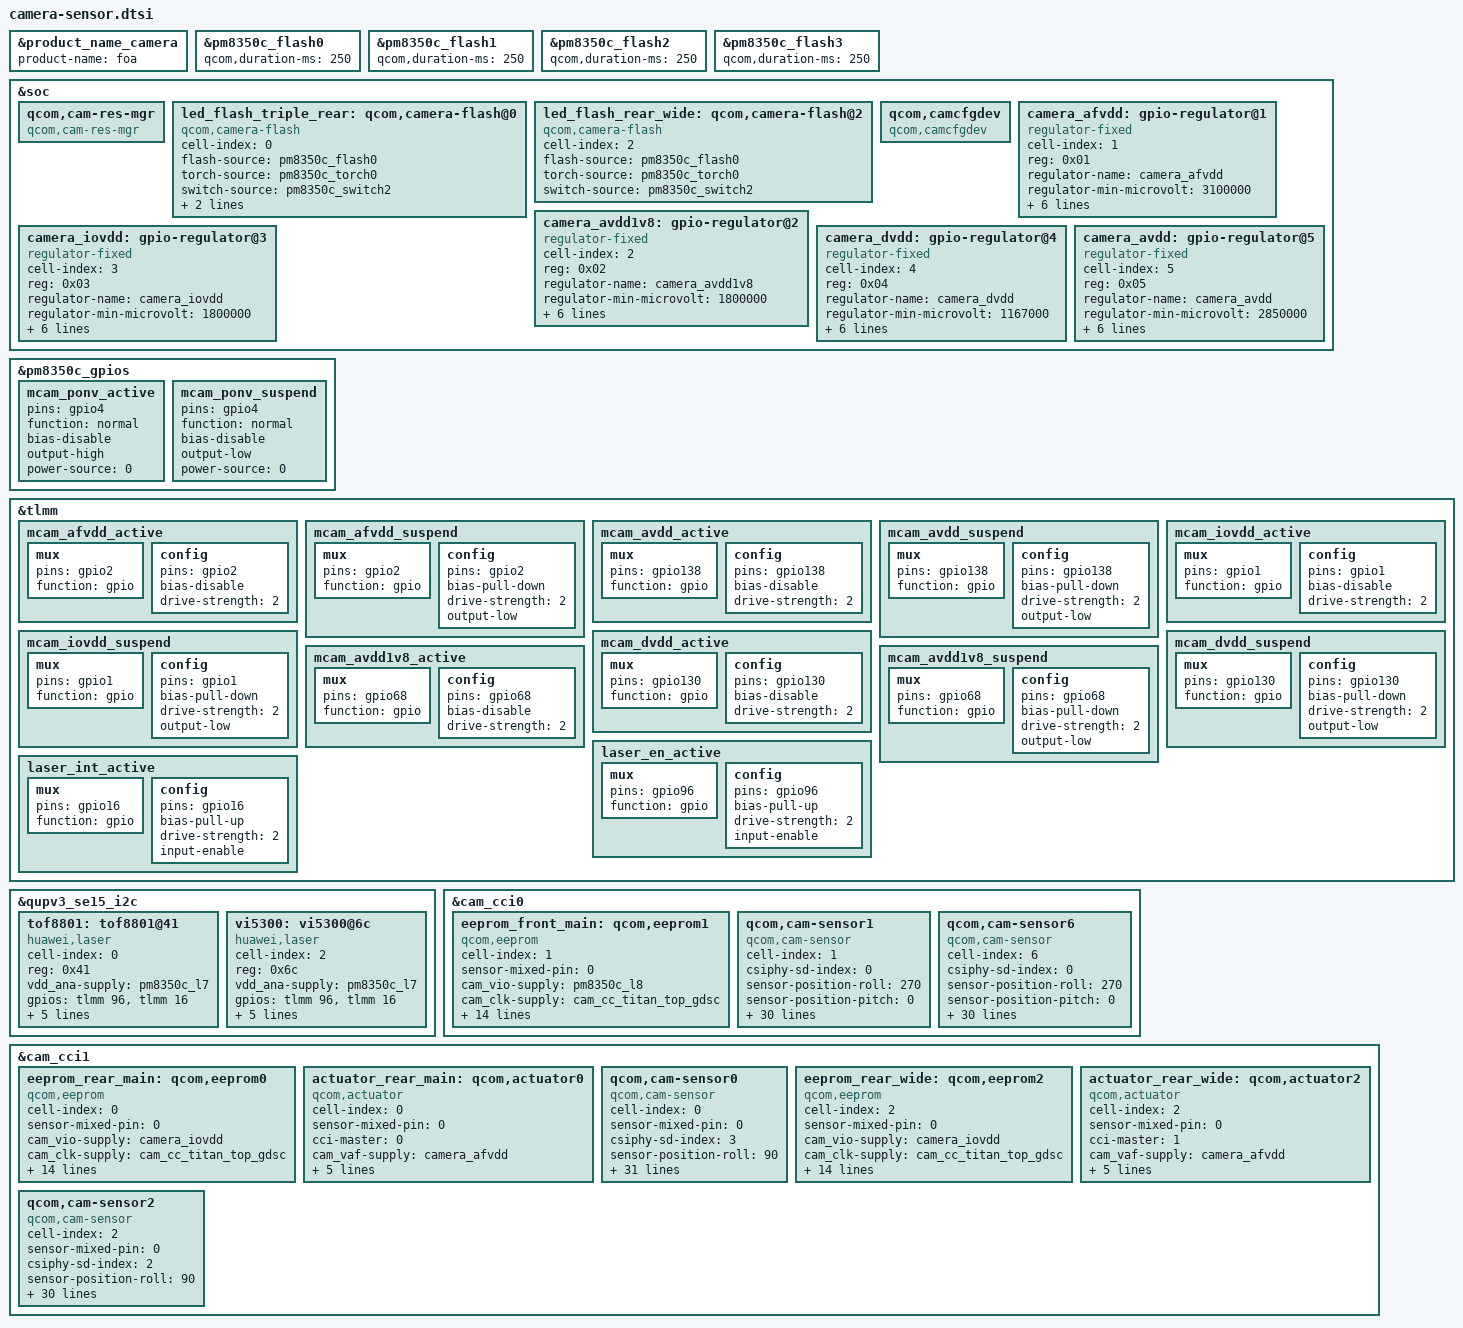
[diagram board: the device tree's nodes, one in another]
#include <dt-bindings/clock/qcom,camcc-yupik.h>

&product_name_camera {
	product-name = "foa";
};

&pm8350c_flash0 {
	qcom,duration-ms = <250>;
};

&pm8350c_flash1 {
	qcom,duration-ms = <250>;
};

&pm8350c_flash2 {
	qcom,duration-ms = <250>;
};

&pm8350c_flash3 {
	qcom,duration-ms = <250>;
};

&soc {
	qcom,cam-res-mgr {
		compatible = "qcom,cam-res-mgr";
		status = "ok";
	};

	led_flash_triple_rear: qcom,camera-flash@0 {
		cell-index = <0>;
		compatible = "qcom,camera-flash";
		flash-source = <&pm8350c_flash0>;
		torch-source = <&pm8350c_torch0>;
		switch-source = <&pm8350c_switch2>;
		torch-light-num = <0>;
		torch-light-name = "torch-light0";
		status = "ok";
	};

	led_flash_rear_wide: qcom,camera-flash@2 {
		cell-index = <2>;
		compatible = "qcom,camera-flash";
		flash-source = <&pm8350c_flash0>;
		torch-source = <&pm8350c_torch0>;
		switch-source = <&pm8350c_switch2>;
		status = "ok";
	};

	qcom,camcfgdev {
		compatible = "qcom,camcfgdev";
		status = "ok";
	};

	camera_afvdd: gpio-regulator@1 {
		cell-index = <1>;
		compatible = "regulator-fixed";
		reg = <0x01>;
		regulator-name = "camera_afvdd";
		regulator-min-microvolt = <3100000>;
		regulator-max-microvolt = <3100000>;
		gpio = <&tlmm 2 0>;
		pinctrl-names = "cam_default", "cam_suspend";
		pinctrl-0 = <&mcam_afvdd_active>;
		pinctrl-1 = <&mcam_afvdd_suspend>;
		startup-delay-us = <1000>;
		enable-active-high;
	};

	camera_avdd1v8: gpio-regulator@2 {
		cell-index = <2>;
		compatible = "regulator-fixed";
		reg = <0x02>;
		regulator-name = "camera_avdd1v8";
		regulator-min-microvolt = <1800000>;
		regulator-max-microvolt = <1800000>;
		gpio = <&tlmm 68 0>;
		pinctrl-names = "cam_default", "cam_suspend";
		pinctrl-0 = <&mcam_avdd1v8_active>;
		pinctrl-1 = <&mcam_avdd1v8_suspend>;
		startup-delay-us = <1000>;
		enable-active-high;
	};

	camera_iovdd: gpio-regulator@3 {
		cell-index = <3>;
		compatible = "regulator-fixed";
		reg = <0x03>;
		regulator-name = "camera_iovdd";
		regulator-min-microvolt = <1800000>;
		regulator-max-microvolt = <1800000>;
		gpio = <&tlmm 1 0>;
		pinctrl-names = "cam_default", "cam_suspend";
		pinctrl-0 = <&mcam_iovdd_active>;
		pinctrl-1 = <&mcam_iovdd_suspend>;
		startup-delay-us = <1000>;
		enable-active-high;
	};

	camera_dvdd: gpio-regulator@4 {
		cell-index = <4>;
		compatible = "regulator-fixed";
		reg = <0x04>;
		regulator-name = "camera_dvdd";
		regulator-min-microvolt = <1167000>;
		regulator-max-microvolt = <1167000>;
		gpio = <&tlmm 130 0>;
		pinctrl-names = "cam_default", "cam_suspend";
		pinctrl-0 = <&mcam_dvdd_active>;
		pinctrl-1 = <&mcam_dvdd_suspend>;
		startup-delay-us = <1000>;
		enable-active-high;
	};

	camera_avdd: gpio-regulator@5 {
		cell-index = <5>;
		compatible = "regulator-fixed";
		reg = <0x05>;
		regulator-name = "camera_avdd";
		regulator-min-microvolt = <2850000>;
		regulator-max-microvolt = <2850000>;
		gpio = <&tlmm 138 0>;
		pinctrl-names = "cam_default", "cam_suspend";
		pinctrl-0 = <&mcam_avdd_active>;
		pinctrl-1 = <&mcam_avdd_suspend>;
		startup-delay-us = <1000>;
		enable-active-high;
	};
};

&pm8350c_gpios {
	mcam_ponv_active: mcam_ponv_active {
		pins = "gpio4";
		function = "normal";
		bias-disable;
		output-high;
		power-source = <0>;
	};
	mcam_ponv_suspend: mcam_ponv_suspend {
		pins = "gpio4";
		function = "normal";
		bias-disable;
		output-low;
		power-source = <0>;
	};
};

&tlmm {
	mcam_afvdd_active: mcam_afvdd_active {
		/* mcam_afvdd for REAR MAIN, REAR WIDE*/
		mux {
			pins = "gpio2";
			function = "gpio";
		};

		config {
			pins = "gpio2";
			bias-disable; /* No PULL */
			drive-strength = <2>; /* 2 MA */
		};
	};

	mcam_afvdd_suspend: mcam_afvdd_suspend {
		/* mcam_avdd */
		mux {
			pins = "gpio2";
			function = "gpio";
		};

		config {
			pins = "gpio2";
			bias-pull-down; /* PULL DOWN */
			drive-strength = <2>; /* 2 MA */
			output-low;
		};
	};

	mcam_avdd_active: mcam_avdd_active {
		/* mcam_avdd */
		mux {
			pins = "gpio138";
			function = "gpio";
		};

		config {
			pins = "gpio138";
			bias-disable; /* No PULL */
			drive-strength = <2>; /* 2 MA */
		};
	};

	mcam_avdd_suspend: mcam_avdd_suspend {
		/* mcam_avdd */
		mux {
			pins = "gpio138";
			function = "gpio";
		};

		config {
			pins = "gpio138";
			bias-pull-down; /* PULL DOWN */
			drive-strength = <2>; /* 2 MA */
			output-low;
		};
	};

	mcam_iovdd_active: mcam_iovdd_active {
		/* mcam_iovdd for REAR MAIN, REAR WIDE */
		mux {
			pins = "gpio1";
			function = "gpio";
		};

		config {
			pins = "gpio1";
			bias-disable; /* No PULL */
			drive-strength = <2>; /* 2 MA */
		};
	};

	mcam_iovdd_suspend: mcam_iovdd_suspend {
		/* mcam_iovdd for REAR MAIN, REAR WIDE */
		mux {
			pins = "gpio1";
			function = "gpio";
		};

		config {
			pins = "gpio1";
			bias-pull-down; /* PULL DOWN */
			drive-strength = <2>; /* 2 MA */
			output-low;
		};
	};

	mcam_dvdd_active: mcam_dvdd_active {
		/* mcam_dvdd */
		mux {
			pins = "gpio130";
			function = "gpio";
		};

		config {
			pins = "gpio130";
			bias-disable; /* No PULL */
			drive-strength = <2>; /* 2 MA */
		};
	};

	mcam_dvdd_suspend: mcam_dvdd_suspend {
		/* mcam_dvdd */
		mux {
			pins = "gpio130";
			function = "gpio";
		};

		config {
			pins = "gpio130";
			bias-pull-down; /* PULL DOWN */
			drive-strength = <2>; /* 2 MA */
			output-low;
		};
	};

	mcam_avdd1v8_active: mcam_avdd1v8_active {
		/* mcam_avdd */
		mux {
			pins = "gpio68";
			function = "gpio";
		};

		config {
			pins = "gpio68";
			bias-disable; /* No PULL */
			drive-strength = <2>; /* 2 MA */
		};
	};

	mcam_avdd1v8_suspend: mcam_avdd1v8_suspend {
		/* mcam_avdd */
		mux {
			pins = "gpio68";
			function = "gpio";
		};

		config {
			pins = "gpio68";
			bias-pull-down; /* PULL DOWN */
			drive-strength = <2>; /* 2 MA */
			output-low;
		};
	};

	laser_en_active: laser_en_active {
		/* laser en pin */
		mux {
			pins = "gpio96";
			function = "gpio";
		};

		config {
			pins = "gpio96";
			bias-pull-up; /* PULL UP */
			drive-strength = <2>; /* 2 MA */
			input-enable;
		};
	};

	laser_int_active: laser_int_active {
		/* laser int pin */
		mux {
			pins = "gpio16";
			function = "gpio";
		};

		config {
			pins = "gpio16";
			bias-pull-up; /* PULL UP */
			drive-strength = <2>; /* 2 MA */
			input-enable;
		};
	};
};

/* laser */
&qupv3_se15_i2c {
	status = "ok";

	tof8801: tof8801@41 {
		cell-index = <0>;
		compatible = "huawei,laser";
		reg = <0x41>;
		vdd_ana-supply = <&pm8350c_l7>;
		gpios = <&tlmm 96 0>,
			<&tlmm 16 0>;
		pinctrl-names = "laser_int_active", "laser_en_active";
		pinctrl-0 = <&laser_int_active>;
		pinctrl-1 = <&laser_en_active>;
		gpio-req-tbl-num = <0>;
		gpio-req-tbl-flags = <0>;
		gpio-req-tbl-label = "CAM_VAF0";
		status = "ok";
	};

	vi5300: vi5300@6c {
		cell-index = <2>;
		compatible = "huawei,laser";
		reg = <0x6c>;
		vdd_ana-supply = <&pm8350c_l7>;
		gpios = <&tlmm 96 0>,
			<&tlmm 16 0>;
		pinctrl-names = "laser_int_active", "laser_en_active";
		pinctrl-0 = <&laser_int_active>;
		pinctrl-1 = <&laser_en_active>;
		gpio-req-tbl-num = <0>;
		gpio-req-tbl-flags = <0>;
		gpio-req-tbl-label = "CAM_VAF0";
		status = "ok";
	};
};

/* cci0: i2c0 i2c1 */
&cam_cci0 {
	/* front main eeprom */
	eeprom_front_main: qcom,eeprom1 {
		cell-index = <1>; /* slotId 1 */
		compatible = "qcom,eeprom";
		sensor-mixed-pin = <0>;
		cam_vio-supply = <&pm8350c_l8>; /* iovdd pm8350c l8 1.8v */
		cam_clk-supply = <&cam_cc_titan_top_gdsc>;
		regulator-names = "cam_vio", "cam_clk";
		rgltr-cntrl-support;
		rgltr-min-voltage = <1800000 0>;
		rgltr-max-voltage = <1850000 0>;
		rgltr-load-current = <40000 0>;
		gpio-no-mux = <0>;
		gpios = <&tlmm 64 0>; /* mclk0 gpio 64 */
		gpio-req-tbl-num = <0>;
		gpio-req-tbl-flags = <1>;
		gpio-req-tbl-label = "CAMIF_MCLK0";
		cci-master = <0>;
		status = "ok";
		clocks = <&camcc CAM_CC_MCLK0_CLK>;
		clock-names = "cam_clk";
		clock-cntl-level = "nominal";
		clock-rates = <19200000>;
	};

	/* front main senosr */
	qcom,cam-sensor1 {
		cell-index = <1>; /* slotId 1 */
		compatible = "qcom,cam-sensor";
		csiphy-sd-index = <0>; /* phy0 */
		sensor-position-roll = <270>;
		sensor-position-pitch = <0>;
		sensor-position-yaw = <0>;
		eeprom-src = <&eeprom_front_main>;
		sensor-mixed-pin = <0>;
		cam_vana-supply = <&camera_avdd>; /* mcam avdd 2.85v */
		cam_vaf-supply = <&camera_afvdd>; /* mcam afvdd 3.1v */
		cam_vio-supply = <&pm8350c_l8>; /* iovdd pm8350c l8 1.8v */
		cam_vdig-supply = <&camera_dvdd>; /* mcan dvdd 1.167v */
		cam_clk-supply = <&cam_cc_titan_top_gdsc>;
		regulator-names = "cam_vana", "cam_vaf", "cam_vio", "cam_vdig", "cam_clk";
		rgltr-cntrl-support;
		rgltr-min-voltage = <2850000 3100000 1800000 1167000 0>;
		rgltr-max-voltage = <2850000 3100000 1850000 1167000 0>;
		rgltr-load-current = <0 0 40000 0 0>;
		gpio-no-mux = <0>;
		pinctrl-names = "cam_default", "cam_suspend";
		pinctrl-0 = <&cam_sensor_mclk0_active>;
		pinctrl-1 = <&cam_sensor_mclk0_suspend>;
		gpios = <&tlmm 64 0>, /* mclk0 gpio 64 */
			<&tlmm 20 0>, /* reset0 gpio 20 */
			<&pm8350c_gpios 4 0>; /* ponv pm8350c_gpios 4 */
		gpio-reset = <1>;
		gpio-mixed1 = <2>;
		gpio-req-tbl-num = <0 1 2>;
		gpio-req-tbl-flags = <1 0 0>;
		gpio-req-tbl-label =  "CAMIF_MCLK0", "CAM_RESET0", "CAM_MIXED1";
		cci-master = <0>; /* i2c0 */
		status = "ok";
		clocks = <&camcc CAM_CC_MCLK0_CLK>;
		clock-names = "cam_clk";
		clock-cntl-level = "nominal";
		clock-rates = <19200000>;
	};

	/* front swing senosr */
	qcom,cam-sensor6 {
		cell-index = <6>; /* slotId 6 */
		compatible = "qcom,cam-sensor";
		csiphy-sd-index = <0>; /* phy0 */
		sensor-position-roll = <270>;
		sensor-position-pitch = <0>;
		sensor-position-yaw = <0>;
		sensor-mixed-pin = <0>;
		cam_vana-supply = <&camera_avdd>; /* mcam avdd 2.85v */
		cam_vaf-supply = <&camera_afvdd>; /* mcam afvdd 3.1v */
		cam_vio-supply = <&pm8350c_l8>;  /* iovdd pm8350c l8 1.8v */
		cam_vdig-supply = <&camera_dvdd>; /* mcan dvdd 1.167v */
		cam_clk-supply = <&cam_cc_titan_top_gdsc>;
		regulator-names = "cam_vana", "cam_vaf", "cam_vio", "cam_vdig", "cam_clk";
		rgltr-cntrl-support;
		rgltr-min-voltage = <2850000 3100000 1800000 1167000 0>;
		rgltr-max-voltage = <2850000 3100000 1850000 1167000 0>;
		rgltr-load-current = <0 0 40000 0 0>; /* value? */
		gpio-no-mux = <0>;
		pinctrl-names = "cam_default", "cam_suspend";
		pinctrl-0 = <&cam_sensor_mclk0_active>;
		pinctrl-1 = <&cam_sensor_mclk0_suspend>;
		gpios = <&tlmm 64 0>, /* mclk0 gpio 64 */
			<&tlmm 20 0>, /* reset0 gpio 20 */
			<&pm8350c_gpios 4 0>; /* ponv pm8350c_gpios 4 */
		gpio-reset = <1>;
		gpio-mixed1 = <2>;
		gpio-req-tbl-num = <0 1 2>;
		gpio-req-tbl-flags = <1 0 0>;
		gpio-req-tbl-label = "CAMIF_MCLK0", "CAM_RESET0", "CAM_MIXED1";
		cci-master = <0>; /* i2c0 */
		status = "ok";
		clocks = <&camcc CAM_CC_MCLK0_CLK>;
		clock-names = "cam_clk";
		clock-cntl-level = "nominal";
		clock-rates = <19200000>;
		ic_position = <1>; /* CAMERA_POSITION_FORE */
	};

};

/* cci1: i2c2、i2c3 */
&cam_cci1 {
	/* rear main eeprrom */
	eeprom_rear_main: qcom,eeprom0 {
		cell-index = <0>; /* slotId 0 eeprom */
		compatible = "qcom,eeprom";
		sensor-mixed-pin = <0>;
		cam_vio-supply = <&camera_iovdd>; /* iovdd 1.8v */
		cam_clk-supply = <&cam_cc_titan_top_gdsc>;
		regulator-names = "cam_vio", "cam_clk";
		rgltr-cntrl-support;
		rgltr-min-voltage = <1800000 0>;
		rgltr-max-voltage = <1800000 0>;
		rgltr-load-current = <0 0>;
		gpio-no-mux = <0>;
		gpios = <&tlmm 66 0>; /* mclk2 gpio 66 */
		gpio-req-tbl-num = <0>;
		gpio-req-tbl-flags = <1>;
		gpio-req-tbl-label = "CAMIF_MCLK2";
		cci-master = <0>;
		status = "ok";
		clocks = <&camcc CAM_CC_MCLK2_CLK>;
		clock-names = "cam_clk";
		clock-cntl-level = "nominal";
		clock-rates = <19200000>;
	};

	/* rear main actuator */
	actuator_rear_main: qcom,actuator0 {
		cell-index = <0>;
		compatible = "qcom,actuator";
		status = "ok";
		sensor-mixed-pin = <0>;
		cci-master = <0>;
		cam_vaf-supply = <&camera_afvdd>; /* afvdd gpio2 3.1v */
		regulator-names = "cam_vaf";
		rgltr-cntrl-support;
		rgltr-min-voltage = <3100000>;
		rgltr-max-voltage = <3100000>;
		rgltr-load-current = <0>;
	};

	/* rear main senosr */
	qcom,cam-sensor0 {
		cell-index = <0>; /* slotId 0 */
		compatible = "qcom,cam-sensor";
		sensor-mixed-pin = <0>;
		csiphy-sd-index = <3>; /* phy3 */
		sensor-position-roll = <90>;
		sensor-position-pitch = <0>;
		sensor-position-yaw = <180>;
		eeprom-src = <&eeprom_rear_main>;
		actuator-src = <&actuator_rear_main>;
		led-flash-src = <&led_flash_triple_rear>;
		cam_vana-supply = <&camera_avdd>; /* mcam avdd 2.85v */
		cam_vana1-supply = <&camera_avdd1v8>;
		cam_vaf-supply = <&camera_afvdd>; /* mcam afvdd 3.1v */
		cam_vio-supply = <&camera_iovdd>; /* mcam iovdd 1.8v */
		cam_vdig-supply = <&camera_dvdd>; /* mcan dvdd 1.167v */
		cam_clk-supply = <&cam_cc_titan_top_gdsc>;
		regulator-names = "cam_vana", "cam_vana1", "cam_vaf", "cam_vio", "cam_vdig", "cam_clk";
		rgltr-cntrl-support;
		rgltr-min-voltage = <2850000 1800000 3100000 1800000 1167000 0>;
		rgltr-max-voltage = <2850000 1800000 3100000 1800000 1167000 0>;
		rgltr-load-current = <0 0 0 0 0 0>; /* value? */
		gpio-no-mux = <0>;
		pinctrl-names = "cam_default", "cam_suspend";
		pinctrl-0 = <&cam_sensor_mclk2_active>;
		pinctrl-1 = <&cam_sensor_mclk2_suspend>;
		gpios = <&tlmm 66 0>, /* mclk2 gpio 66 */
			<&tlmm 77 0>; /* reset2 gpio 77 */
		gpio-reset = <1>;
		gpio-req-tbl-num = <0 1>;
		gpio-req-tbl-flags = <1 0>;
		gpio-req-tbl-label = "CAMIF_MCLK2", "CAM_RESET2";
		cci-master = <0>; /* i2c2 */
		status = "ok";
		clocks = <&camcc CAM_CC_MCLK2_CLK>;
		clock-names = "cam_clk";
		clock-cntl-level = "nominal";
		clock-rates = <19200000>;
	};

	/* rear wide eeprom */
	eeprom_rear_wide: qcom,eeprom2 {
		cell-index = <2>; /* slotId 2 */
		compatible = "qcom,eeprom";
		sensor-mixed-pin = <0>;
		cam_vio-supply = <&camera_iovdd>; /* iovdd 1.8v */
		cam_clk-supply = <&cam_cc_titan_top_gdsc>;
		regulator-names = "cam_vio", "cam_clk";
		rgltr-cntrl-support;
		rgltr-min-voltage = <1800000 0>;
		rgltr-max-voltage = <1800000 0>;
		rgltr-load-current = <0 0>;
		gpio-no-mux = <0>;
		gpios = <&tlmm 67 0>; /* mclk3 gpio 67 */
		gpio-req-tbl-num = <0>;
		gpio-req-tbl-flags = <1>;
		gpio-req-tbl-label = "CAMIF_MCLK3";
		cci-master = <1>;
		status = "ok";
		clocks = <&camcc CAM_CC_MCLK3_CLK>;
		clock-names = "cam_clk";
		clock-cntl-level = "nominal";
		clock-rates = <19200000>;
	};

	/* rear wide actuator */
	actuator_rear_wide: qcom,actuator2 {
		cell-index = <2>;
		compatible = "qcom,actuator";
		status = "ok";
		sensor-mixed-pin = <0>;
		cci-master = <1>;
		cam_vaf-supply = <&camera_afvdd>; /* afvdd gpio2 3.1v */
		regulator-names = "cam_vaf";
		rgltr-cntrl-support;
		rgltr-min-voltage = <3100000>;
		rgltr-max-voltage = <3100000>;
		rgltr-load-current = <0>;
	};

	/* rear wide senosr */
	qcom,cam-sensor2 {
		cell-index = <2>; /* slotId 2 */
		compatible = "qcom,cam-sensor";
		sensor-mixed-pin = <0>;
		csiphy-sd-index = <2>; /* phy2 */
		sensor-position-roll = <90>;
		sensor-position-pitch = <0>;
		sensor-position-yaw = <180>;
		eeprom-src = <&eeprom_rear_wide>;
		actuator-src = <&actuator_rear_wide>;
		led-flash-src = <&led_flash_rear_wide>;
		cam_vana-supply = <&camera_avdd>; /* mcam avdd 2.85v */
		cam_vaf-supply = <&camera_afvdd>; /* mcam afvdd 3.1v */
		cam_vio-supply = <&camera_iovdd>; /* mcam iovdd 1.8v */
		cam_vdig-supply = <&pm7325_l8>; /* dvdd pm7325 l8 */
		cam_clk-supply = <&cam_cc_titan_top_gdsc>;
		regulator-names = "cam_vana", "cam_vaf", "cam_vio", "cam_vdig", "cam_clk";
		rgltr-cntrl-support;
		rgltr-min-voltage = <2850000 3100000 1800000 1210000 0>;
		rgltr-max-voltage = <2850000 3100000 1800000 1220000 0>;
		rgltr-load-current = <0 0 0 200000 0>; /* value? */
		gpio-no-mux = <0>;
		pinctrl-names = "cam_default", "cam_suspend";
		pinctrl-0 = <&cam_sensor_mclk3_active>;
		pinctrl-1 = <&cam_sensor_mclk3_suspend>;
		gpios = <&tlmm 67 0>, /* mclk3 gpio 67 */
			<&tlmm 78 0>; /* reset3 gpio 78 */
		gpio-reset = <1>;
		gpio-req-tbl-num = <0 1>;
		gpio-req-tbl-flags = <1 0>;
		gpio-req-tbl-label = "CAMIF_MCLK3", "CAM_RESET3";
		cci-master = <1>; /* i2c3 */
		status = "ok";
		clocks = <&camcc CAM_CC_MCLK3_CLK>;
		clock-names = "cam_clk";
		clock-cntl-level = "nominal";
		clock-rates = <19200000>;
	};
};

